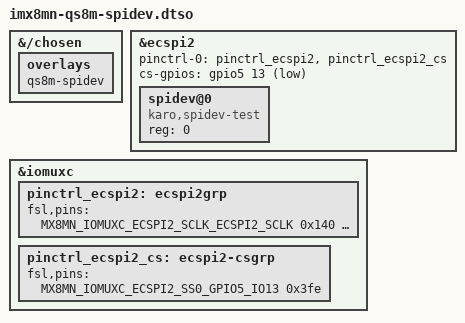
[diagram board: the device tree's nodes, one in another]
// SPDX-License-Identifier: (GPL-2.0 OR BSD-3-Clause)
/*
 * Copyright (C) 2023 Lothar Waßmann <LW@KARO-electronics.de>
 */

/dts-v1/;
/plugin/;

#include <dt-bindings/gpio/gpio.h>
#include "imx8mn-pinfunc.h"

&{/chosen} {
	overlays {
		qs8m-spidev;
	};
};

&ecspi2 {
	pinctrl-names = "default";
	pinctrl-0 = <&pinctrl_ecspi2 &pinctrl_ecspi2_cs>;
	cs-gpios = <&gpio5 13 GPIO_ACTIVE_LOW>;
	status = "okay";

	spidev@0 {
		reg = <0>;
		compatible = "karo,spidev-test";
	};
};

&iomuxc {
	pinctrl_ecspi2: ecspi2grp {
		fsl,pins = <
			MX8MN_IOMUXC_ECSPI2_SCLK_ECSPI2_SCLK		0x140
			MX8MN_IOMUXC_ECSPI2_MOSI_ECSPI2_MOSI		0x140
			MX8MN_IOMUXC_ECSPI2_MISO_ECSPI2_MISO		0x140
			MX8MN_IOMUXC_ECSPI2_SS0_GPIO5_IO13		0x140
		>;
	};

	pinctrl_ecspi2_cs: ecspi2-csgrp {
		fsl,pins = <
			MX8MN_IOMUXC_ECSPI2_SS0_GPIO5_IO13		0x3fe
		>;
	};
};
